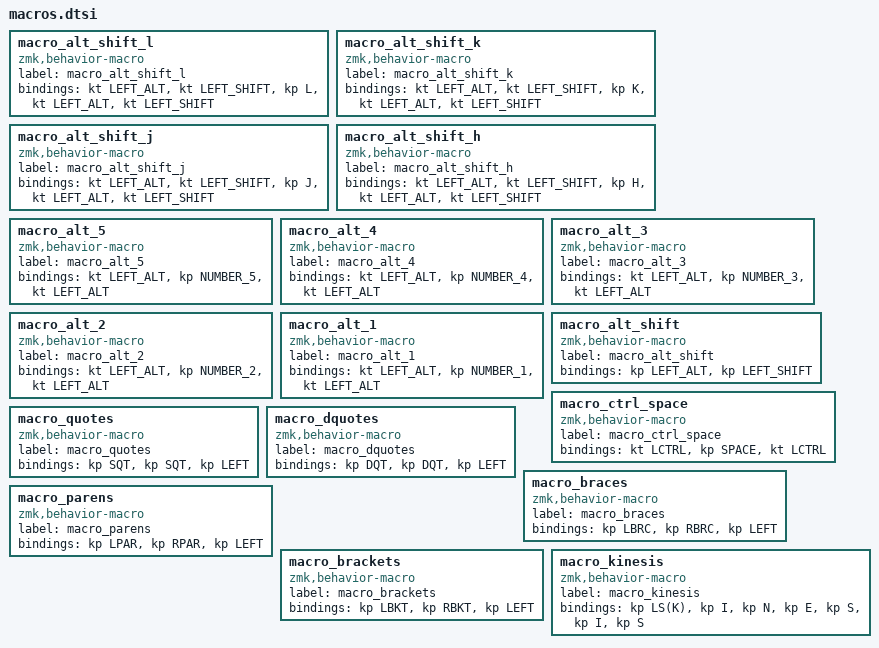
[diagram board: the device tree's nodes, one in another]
macro_alt_shift_l: macro_alt_shift_l{
compatible = "zmk,behavior-macro";
label = "macro_alt_shift_l";
#binding-cells = <0>;
bindings = <&kt LEFT_ALT>, <&kt LEFT_SHIFT>, <&kp L>, <&kt LEFT_ALT>, <&kt LEFT_SHIFT>;
};
macro_alt_shift_k: macro_alt_shift_k{
compatible = "zmk,behavior-macro";
label = "macro_alt_shift_k";
#binding-cells = <0>;
bindings = <&kt LEFT_ALT>, <&kt LEFT_SHIFT>, <&kp K>, <&kt LEFT_ALT>, <&kt LEFT_SHIFT>;
};
macro_alt_shift_j: macro_alt_shift_j{
compatible = "zmk,behavior-macro";
label = "macro_alt_shift_j";
#binding-cells = <0>;
bindings = <&kt LEFT_ALT>, <&kt LEFT_SHIFT>, <&kp J>, <&kt LEFT_ALT>, <&kt LEFT_SHIFT>;
};
macro_alt_shift_h: macro_alt_shift_h{
compatible = "zmk,behavior-macro";
label = "macro_alt_shift_h";
#binding-cells = <0>;
bindings = <&kt LEFT_ALT>, <&kt LEFT_SHIFT>, <&kp H>, <&kt LEFT_ALT>, <&kt LEFT_SHIFT>;
};
macro_alt_5: macro_alt_5{
compatible = "zmk,behavior-macro";
label = "macro_alt_5";
#binding-cells = <0>;
bindings = <&kt LEFT_ALT>, <&kp NUMBER_5>, <&kt LEFT_ALT>;
};
macro_alt_4: macro_alt_4{
compatible = "zmk,behavior-macro";
label = "macro_alt_4";
#binding-cells = <0>;
bindings = <&kt LEFT_ALT>, <&kp NUMBER_4>, <&kt LEFT_ALT>;
};
macro_alt_3: macro_alt_3{
compatible = "zmk,behavior-macro";
label = "macro_alt_3";
#binding-cells = <0>;
bindings = <&kt LEFT_ALT>, <&kp NUMBER_3>, <&kt LEFT_ALT>;
};
macro_alt_2: macro_alt_2{
compatible = "zmk,behavior-macro";
label = "macro_alt_2";
#binding-cells = <0>;
bindings = <&kt LEFT_ALT>, <&kp NUMBER_2>, <&kt LEFT_ALT>;
};
macro_alt_1: macro_alt_1{
compatible = "zmk,behavior-macro";
label = "macro_alt_1";
#binding-cells = <0>;
bindings = <&kt LEFT_ALT>, <&kp NUMBER_1>, <&kt LEFT_ALT>;
};
macro_alt_shift: macro_alt_shift{
compatible = "zmk,behavior-macro";
label = "macro_alt_shift";
#binding-cells = <0>;
bindings = <&kp LEFT_ALT>, <&kp LEFT_SHIFT>;
};
macro_ctrl_space: macro_ctrl_space{
compatible = "zmk,behavior-macro";
label = "macro_ctrl_space";
#binding-cells = <0>;
bindings = <&kt LCTRL>, <&kp SPACE>, <&kt LCTRL>;
};
macro_quotes: macro_quotes{
compatible = "zmk,behavior-macro";
label = "macro_quotes";
#binding-cells = <0>;
bindings = <&kp SQT>, <&kp SQT>, <&kp LEFT>;
};
macro_dquotes: macro_dquotes{
compatible = "zmk,behavior-macro";
label = "macro_dquotes";
#binding-cells = <0>;
bindings = <&kp DQT>, <&kp DQT>, <&kp LEFT>;
};
macro_braces: macro_braces{
compatible = "zmk,behavior-macro";
label = "macro_braces";
#binding-cells = <0>;
bindings = <&kp LBRC>, <&kp RBRC>, <&kp LEFT>;
};
macro_parens: macro_parens{
compatible = "zmk,behavior-macro";
label = "macro_parens";
#binding-cells = <0>;
bindings = <&kp LPAR>, <&kp RPAR>, <&kp LEFT>;
};
macro_brackets: macro_brackets{
compatible = "zmk,behavior-macro";
label = "macro_brackets";
#binding-cells = <0>;
bindings = <&kp LBKT>, <&kp RBKT>, <&kp LEFT>;
};
macro_kinesis: macro_kinesis{
compatible = "zmk,behavior-macro";
label = "macro_kinesis";
#binding-cells = <0>;
bindings = <&kp LS(K)>, <&kp I>, <&kp N>, <&kp E>, <&kp S>, <&kp I>, <&kp S>;
};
